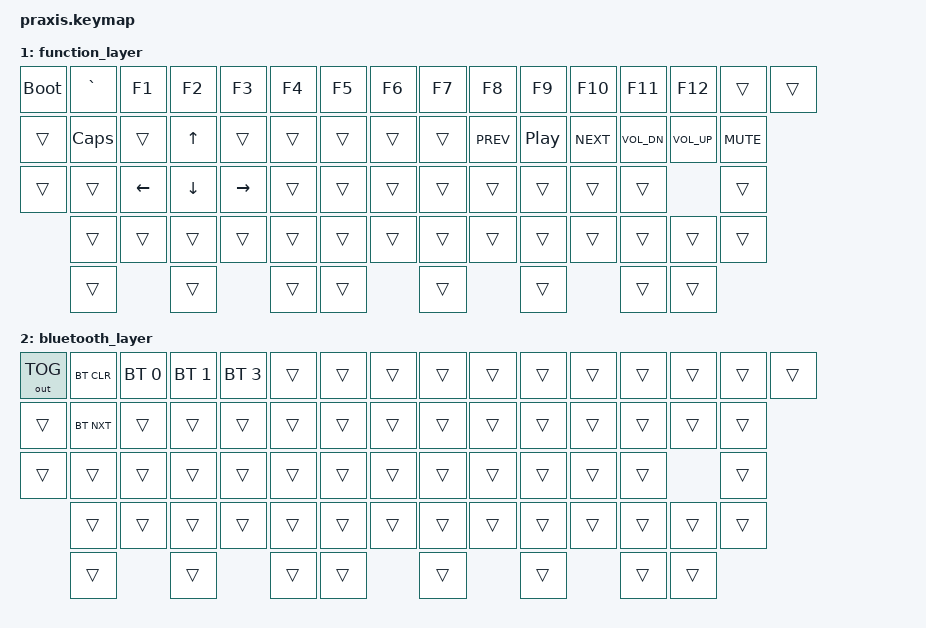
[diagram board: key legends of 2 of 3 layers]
/*
 * Copyright (c) 2021 The ZMK Contributors
 *
 * SPDX-License-Identifier: MIT
 */

#include <behaviors.dtsi>
#include <dt-bindings/zmk/keys.h>
#include <dt-bindings/zmk/bt.h>
#include <dt-bindings/zmk/outputs.h>

#define DEFAULT    0
#define FUNCTION   1
#define BLUETOOTH  2

/ {
        keymap {
                compatible = "zmk,keymap";

                default_layer {
                        bindings = <
   &kp ESC      &kp ESC      &kp N1  &kp N2    &kp N3 &kp N4    &kp N5    &kp N6   &kp N7     &kp N8    &kp N9       &kp N0     &kp MINUS  &kp EQUAL   &kp BSLH    &kp PSCRN
   &kp HOME     &kp TAB      &kp Q   &kp W     &kp E  &kp R     &kp T     &kp Y    &kp U      &kp I     &kp O        &kp P      &kp LBKT   &kp RBKT    &kp BSPC
   &kp END      &mo FUNCTION &kp A   &kp S     &kp D  &kp F     &kp G     &kp H    &kp J      &kp K     &kp L        &kp SEMI   &kp SQT                &kp ENTER                    
                &kp LSHFT    &kp Z   &kp X     &kp C  &kp V     &kp B     &kp B    &kp N      &kp M     &kp COMMA    &kp DOT    &kp SLASH  &kp RSHFT   &mo BLUETOOTH
                &kp LCTRL            &kp LALT         &kp SPACE &kp LGUI           &kp SPACE            &kp RALT                           &kp RCTRL
                               >;
                        };

                function_layer {
                        bindings = <
   &bootloader  &kp GRAVE    &kp F1     &kp F2    &kp F3    &kp F4   &kp F5   &kp F6   &kp F7     &kp F8    &kp F9       &kp F10   &kp F11      &kp F12      &trans      &trans
   &trans       &kp CAPS     &trans     &kp UP    &trans    &trans   &trans   &trans   &trans    &kp C_PREV &kp C_PP    &kp C_NEXT &kp C_VOL_DN &kp C_VOL_UP &kp C_MUTE
   &trans       &trans       &kp LEFT   &kp DOWN  &kp RIGHT &trans   &trans   &trans   &trans     &trans    &trans       &trans    &trans                    &trans
                &trans       &trans     &trans    &trans    &trans   &trans   &trans   &trans     &trans    &trans       &trans    &trans       &trans       &trans
                &trans                  &trans              &trans   &trans            &trans               &trans                 &trans       &trans
                                >;
                        };

                bluetooth_layer {
                        bindings = <
   &out OUT_TOG &bt BT_CLR   &bt BT_SEL 0  &bt BT_SEL 1 &bt BT_SEL 3 &trans   &trans   &trans   &trans     &trans    &trans       &trans    &trans     &trans      &trans      &trans
   &trans       &bt BT_NXT   &trans        &trans       &trans       &trans   &trans   &trans   &trans     &trans    &trans       &trans    &trans     &trans      &trans
   &trans       &trans       &trans        &trans       &trans       &trans   &trans   &trans   &trans     &trans    &trans       &trans    &trans                 &trans
                &trans       &trans        &trans       &trans       &trans   &trans   &trans   &trans     &trans    &trans       &trans    &trans     &trans      &trans
                &trans                     &trans                    &trans   &trans            &trans               &trans                 &trans     &trans
                                >;
                        };
        };
};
